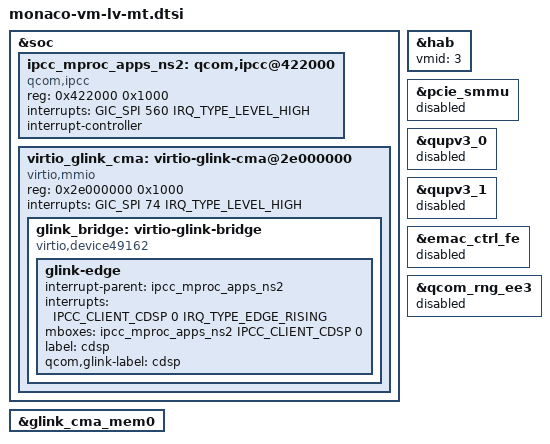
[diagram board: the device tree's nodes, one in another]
// SPDX-License-Identifier: BSD-3-Clause
/*
 * Copyright (c) Qualcomm Technologies, Inc. and/or its subsidiaries.
 */

#include <dt-bindings/mailbox/qcom-ipcc.h>

&soc {
	ipcc_mproc_apps_ns2: qcom,ipcc@422000 {
		compatible = "qcom,ipcc";
		reg = <0x422000 0x1000>;
		interrupts = <GIC_SPI 560 IRQ_TYPE_LEVEL_HIGH>;
		interrupt-controller;
		#interrupt-cells = <3>;
		#mbox-cells = <2>;
	};

	virtio_glink_cma: virtio-glink-cma@2e000000 {
		compatible = "virtio,mmio";
		reg = <0x2e000000 0x1000>;
		interrupts = <GIC_SPI 74 IRQ_TYPE_LEVEL_HIGH>;

		glink_bridge: virtio-glink-bridge {
			compatible = "virtio,device49162"; /* VIRTIO_ID: 0xC00A */

			glink-edge {
				interrupt-parent = <&ipcc_mproc_apps_ns2>;
				interrupts = <IPCC_CLIENT_CDSP 0 IRQ_TYPE_EDGE_RISING>;
				mboxes = <&ipcc_mproc_apps_ns2 IPCC_CLIENT_CDSP 0>;
				label = "cdsp";
				qcom,glink-label = "cdsp";
			};
		};
	};
};

&hab {
	vmid = <3>;
};

&pcie_smmu {
	status = "disabled";
};

&qupv3_0 {
	status = "disabled";
};

&qupv3_1 {
	status = "disabled";
};

&glink_cma_mem0 {
	status = "okay";
};

&emac_ctrl_fe {
	status = "disabled";
};

&qcom_rng_ee3 {
	status = "disabled";
};
